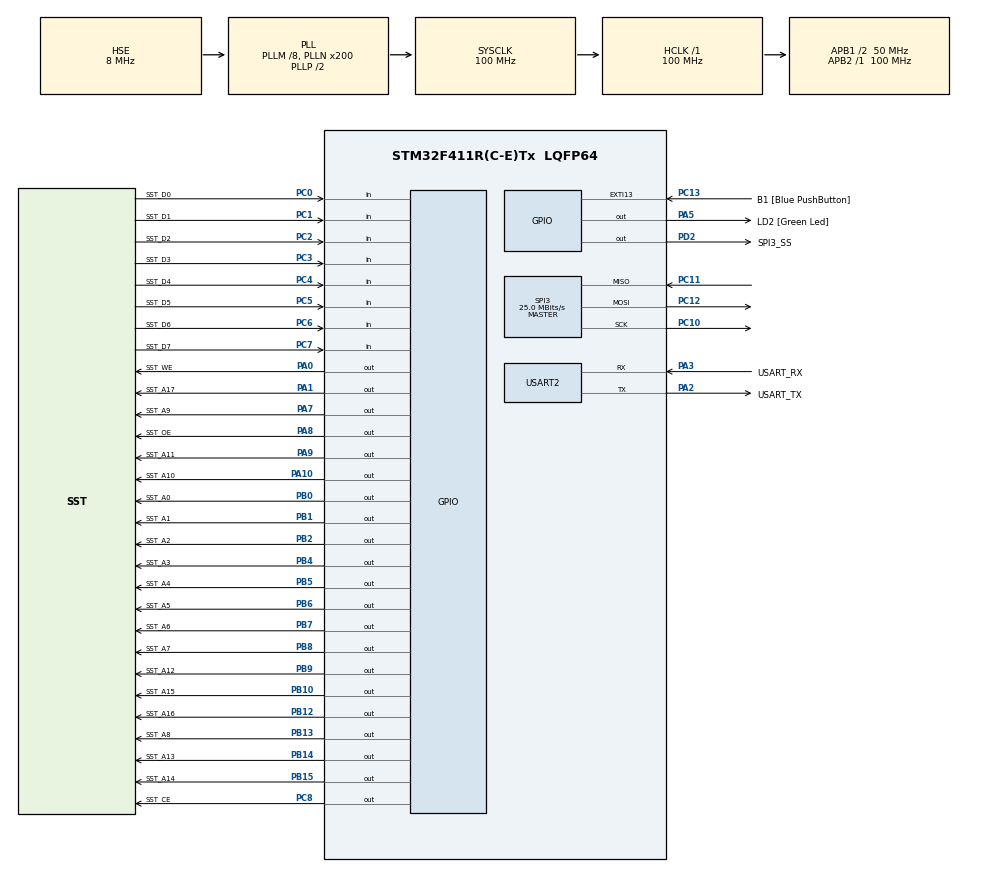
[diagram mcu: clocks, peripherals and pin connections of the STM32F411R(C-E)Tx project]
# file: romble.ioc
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FREERTOS.Tasks01=defaultTask,24,128,StartDefaultTask,Default,NULL,Dynamic,NULL,NULL;cli,40,1024,StartCLITask,Default,NULL,Dynamic,NULL,NULL
FREERTOS.configCHECK_FOR_STACK_OVERFLOW=0
Mcu.Family=STM32F4
Mcu.Name=STM32F411R(C-E)Tx
Mcu.Package=LQFP64
NVIC.PriorityGroup=NVIC_PRIORITYGROUP_4
NVIC.TIM1_BRK_TIM9_IRQn=true\:0\:0\:false\:false\:true\:false\:false\:true
NVIC.TimeBase=TIM1_BRK_TIM9_IRQn
NVIC.TimeBaseIP=TIM9
PA0-WKUP.GPIO_Label=SST_WE
PA0-WKUP.PinState=GPIO_PIN_SET
PA0-WKUP.Signal=GPIO_Output
PA1.GPIO_Label=SST_A17
PA1.Signal=GPIO_Output
PA10.GPIO_Label=SST_A10
PA10.Signal=GPIO_Output
PA13.GPIO_Label=TMS
PA13.Mode=Serial_Wire
PA13.Signal=SYS_JTMS-SWDIO
PA14.GPIO_Label=TCK
PA14.Mode=Serial_Wire
PA14.Signal=SYS_JTCK-SWCLK
PA2.GPIO_Label=USART_TX
PA2.Mode=Asynchronous
PA2.Signal=USART2_TX
PA3.GPIO_Label=USART_RX
PA3.Mode=Asynchronous
PA3.Signal=USART2_RX
PA5.GPIO_Label=LD2 [Green Led]
PA5.Signal=GPIO_Output
PA7.GPIO_Label=SST_A9
PA7.Signal=GPIO_Output
PA8.GPIO_Label=SST_OE
PA8.PinState=GPIO_PIN_SET
PA8.Signal=GPIO_Output
PA9.GPIO_Label=SST_A11
PA9.Signal=GPIO_Output
PB0.GPIO_Label=SST_A0
PB0.Signal=GPIO_Output
PB1.GPIO_Label=SST_A1
PB1.Signal=GPIO_Output
PB10.GPIO_Label=SST_A15
PB10.Signal=GPIO_Output
PB12.GPIO_Label=SST_A16
PB12.Signal=GPIO_Output
PB13.GPIO_Label=SST_A8
PB13.Signal=GPIO_Output
PB14.GPIO_Label=SST_A13
PB14.Signal=GPIO_Output
PB15.GPIO_Label=SST_A14
PB15.Signal=GPIO_Output
PB2.GPIO_Label=SST_A2
PB2.Signal=GPIO_Output
PB3.GPIO_Label=SWO
PB3.Signal=SYS_JTDO-SWO
PB4.GPIO_Label=SST_A3
PB4.Signal=GPIO_Output
PB5.GPIO_Label=SST_A4
PB5.Signal=GPIO_Output
PB6.GPIO_Label=SST_A5
PB6.Signal=GPIO_Output
PB7.GPIO_Label=SST_A6
PB7.Signal=GPIO_Output
PB8.GPIO_Label=SST_A7
PB8.Signal=GPIO_Output
PB9.GPIO_Label=SST_A12
PB9.Signal=GPIO_Output
PC0.GPIO_Label=SST_D0
PC0.GPIO_PuPd=GPIO_PULLUP
PC0.Signal=GPIO_Input
PC1.GPIO_Label=SST_D1
PC1.GPIO_PuPd=GPIO_PULLUP
PC1.Signal=GPIO_Input
PC10.Mode=Full_Duplex_Master
PC10.Signal=SPI3_SCK
PC11.Mode=Full_Duplex_Master
PC11.Signal=SPI3_MISO
PC12.Mode=Full_Duplex_Master
PC12.Signal=SPI3_MOSI
PC13-ANTI_TAMP.GPIO_Label=B1 [Blue PushButton]
PC13-ANTI_TAMP.GPIO_ModeDefaultEXTI=GPIO_MODE_IT_FALLING
PC13-ANTI_TAMP.Signal=GPXTI13
PC14-OSC32_IN.Mode=LSE-External-Oscillator
PC14-OSC32_IN.Signal=RCC_OSC32_IN
PC15-OSC32_OUT.Mode=LSE-External-Oscillator
PC15-OSC32_OUT.Signal=RCC_OSC32_OUT
PC2.GPIO_Label=SST_D2
PC2.GPIO_PuPd=GPIO_PULLUP
PC2.Signal=GPIO_Input
PC3.GPIO_Label=SST_D3
PC3.GPIO_PuPd=GPIO_PULLUP
PC3.Signal=GPIO_Input
PC4.GPIO_Label=SST_D4
PC4.GPIO_PuPd=GPIO_PULLUP
PC4.Signal=GPIO_Input
PC5.GPIO_Label=SST_D5
PC5.GPIO_PuPd=GPIO_PULLUP
PC5.Signal=GPIO_Input
PC6.GPIO_Label=SST_D6
PC6.GPIO_PuPd=GPIO_PULLUP
PC6.Signal=GPIO_Input
PC7.GPIO_Label=SST_D7
PC7.GPIO_PuPd=GPIO_PULLUP
PC7.Signal=GPIO_Input
PC8.GPIO_Label=SST_CE
PC8.PinState=GPIO_PIN_SET
PC8.Signal=GPIO_Output
PD2.GPIO_Label=SPI3_SS
PD2.GPIO_ModeDefaultOutputPP=GPIO_MODE_OUTPUT_OD
PD2.PinState=GPIO_PIN_SET
PD2.Signal=GPIO_Output
PH0\ -\ OSC_IN.Mode=HSE-External-Clock-Source
PH0\ -\ OSC_IN.Signal=RCC_OSC_IN
PH1\ -\ OSC_OUT.Mode=HSE-External-Clock-Source
PH1\ -\ OSC_OUT.Signal=RCC_OSC_OUT
ProjectManager.HeapSize=0x200
ProjectManager.StackSize=0x400
ProjectManager.TargetToolchain=Makefile
RCC.48MHZClocksFreq_Value=20000000
RCC.AHBFreq_Value=100000000
RCC.APB1CLKDivider=RCC_HCLK_DIV2
RCC.APB1Freq_Value=50000000
RCC.APB1TimFreq_Value=100000000
RCC.APB2Freq_Value=100000000
RCC.APB2TimFreq_Value=100000000
RCC.CortexFreq_Value=100000000
RCC.FLatency-AdvancedSettings=FLASH_LATENCY_3
RCC.HCLKFreq_Value=100000000
RCC.HSE_VALUE=8000000
RCC.HSI_VALUE=16000000
RCC.PLLM=8
RCC.PLLN=200
RCC.PLLQ=10
RCC.PLLSourceVirtual=RCC_PLLSOURCE_HSE
RCC.SYSCLKFreq_VALUE=100000000
RCC.SYSCLKSource=RCC_SYSCLKSOURCE_PLLCLK
RCC.VCOOutputFreq_Value=200000000
SPI3.CalculateBaudRate=25.0 MBits/s
SPI3.Direction=SPI_DIRECTION_2LINES
SPI3.Mode=SPI_MODE_MASTER
SPI3.VirtualType=VM_MASTER
USART2.VirtualMode=VM_ASYNC
VP_FREERTOS_VS_CMSIS_V2.Mode=CMSIS_V2
VP_SYS_VS_tim9.Mode=TIM9
board=NUCLEO-F411RE

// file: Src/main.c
/* USER CODE BEGIN Header */
/**
  ******************************************************************************
  * @file           : main.c
  * @brief          : Main program body
  ******************************************************************************
  * @attention
  *
  * <h2><center>&copy; Copyright (c) 2020 STMicroelectronics.
  * All rights reserved.</center></h2>
  *
  * This software component is licensed by ST under Ultimate Liberty license
  * SLA0044, the "License"; You may not use this file except in compliance with
  * the License. You may obtain a copy of the License at:
  *                             www.st.com/SLA0044
  *
  ******************************************************************************
  */
/* USER CODE END Header */

#include "main.h"
#include "cmsis_os.h"

/* USER CODE BEGIN Includes */
#include "cli.h"

/* USER CODE END Includes */

SPI_HandleTypeDef hspi3;

UART_HandleTypeDef huart2;

osThreadId_t defaultTaskHandle;
osThreadId_t cliHandle;

void SystemClock_Config(void);
static void MX_GPIO_Init(void);
static void MX_USART2_UART_Init(void);
static void MX_SPI3_Init(void);
void StartDefaultTask(void *argument);
void StartCLITask(void *argument);

int main(void)
{

  /* MCU Configuration--------------------------------------------------------*/

  /* Reset of all peripherals, Initializes the Flash interface and the Systick. */
  HAL_Init();

  /* Configure the system clock */
  SystemClock_Config();

  /* Initialize all configured peripherals */
  MX_GPIO_Init();
  MX_USART2_UART_Init();
  MX_SPI3_Init();

  osKernelInitialize();

  /* Create the thread(s) */
  /* definition and creation of defaultTask */
  const osThreadAttr_t defaultTask_attributes = {
    .name = "defaultTask",
    .priority = (osPriority_t) osPriorityNormal,
    .stack_size = 128
  };
  defaultTaskHandle = osThreadNew(StartDefaultTask, NULL, &defaultTask_attributes);

  /* definition and creation of cli */
  const osThreadAttr_t cli_attributes = {
    .name = "cli",
    .priority = (osPriority_t) osPriorityHigh,
    .stack_size = 1024
  };
  cliHandle = osThreadNew(StartCLITask, NULL, &cli_attributes);

  /* Start scheduler */
  osKernelStart();

  /* We should never get here as control is now taken by the scheduler */

  /* Infinite loop */
  while (1)
  {

  }
}

void SystemClock_Config(void)
{
  RCC_OscInitTypeDef RCC_OscInitStruct = {0};
  RCC_ClkInitTypeDef RCC_ClkInitStruct = {0};

  /** Configure the main internal regulator output voltage
  */
  __HAL_RCC_PWR_CLK_ENABLE();
  __HAL_PWR_VOLTAGESCALING_CONFIG(PWR_REGULATOR_VOLTAGE_SCALE1);
  /** Initializes the CPU, AHB and APB busses clocks
  */
  RCC_OscInitStruct.OscillatorType = RCC_OSCILLATORTYPE_HSE;
  RCC_OscInitStruct.HSEState = RCC_HSE_BYPASS;
  RCC_OscInitStruct.PLL.PLLState = RCC_PLL_ON;
  RCC_OscInitStruct.PLL.PLLSource = RCC_PLLSOURCE_HSE;
  RCC_OscInitStruct.PLL.PLLM = 8;
  RCC_OscInitStruct.PLL.PLLN = 200;
  RCC_OscInitStruct.PLL.PLLP = RCC_PLLP_DIV2;
  RCC_OscInitStruct.PLL.PLLQ = 10;
  if (HAL_RCC_OscConfig(&RCC_OscInitStruct) != HAL_OK)
  {
    Error_Handler();
  }
  /** Initializes the CPU, AHB and APB busses clocks
  */
  RCC_ClkInitStruct.ClockType = RCC_CLOCKTYPE_HCLK|RCC_CLOCKTYPE_SYSCLK
                              |RCC_CLOCKTYPE_PCLK1|RCC_CLOCKTYPE_PCLK2;
  RCC_ClkInitStruct.SYSCLKSource = RCC_SYSCLKSOURCE_PLLCLK;
  RCC_ClkInitStruct.AHBCLKDivider = RCC_SYSCLK_DIV1;
  RCC_ClkInitStruct.APB1CLKDivider = RCC_HCLK_DIV2;
  RCC_ClkInitStruct.APB2CLKDivider = RCC_HCLK_DIV1;

  if (HAL_RCC_ClockConfig(&RCC_ClkInitStruct, FLASH_LATENCY_3) != HAL_OK)
  {
    Error_Handler();
  }
}

static void MX_SPI3_Init(void)
{

  /* SPI3 parameter configuration*/
  hspi3.Instance = SPI3;
  hspi3.Init.Mode = SPI_MODE_MASTER;
  hspi3.Init.Direction = SPI_DIRECTION_2LINES;
  hspi3.Init.DataSize = SPI_DATASIZE_8BIT;
  hspi3.Init.CLKPolarity = SPI_POLARITY_LOW;
  hspi3.Init.CLKPhase = SPI_PHASE_1EDGE;
  hspi3.Init.NSS = SPI_NSS_SOFT;
  hspi3.Init.BaudRatePrescaler = SPI_BAUDRATEPRESCALER_128;
  hspi3.Init.FirstBit = SPI_FIRSTBIT_MSB;
  hspi3.Init.TIMode = SPI_TIMODE_DISABLE;
  hspi3.Init.CRCCalculation = SPI_CRCCALCULATION_DISABLE;
  hspi3.Init.CRCPolynomial = 10;
  if (HAL_SPI_Init(&hspi3) != HAL_OK)
  {
    Error_Handler();
  }

}

static void MX_USART2_UART_Init(void)
{

  huart2.Instance = USART2;
  huart2.Init.BaudRate = 115200;
  huart2.Init.WordLength = UART_WORDLENGTH_8B;
  huart2.Init.StopBits = UART_STOPBITS_1;
  huart2.Init.Parity = UART_PARITY_NONE;
  huart2.Init.Mode = UART_MODE_TX_RX;
  huart2.Init.HwFlowCtl = UART_HWCONTROL_NONE;
  huart2.Init.OverSampling = UART_OVERSAMPLING_16;
  if (HAL_UART_Init(&huart2) != HAL_OK)
  {
    Error_Handler();
  }

}

static void MX_GPIO_Init(void)
{
  GPIO_InitTypeDef GPIO_InitStruct = {0};

  /* GPIO Ports Clock Enable */
  __HAL_RCC_GPIOC_CLK_ENABLE();
  __HAL_RCC_GPIOH_CLK_ENABLE();
  __HAL_RCC_GPIOA_CLK_ENABLE();
  __HAL_RCC_GPIOB_CLK_ENABLE();
  __HAL_RCC_GPIOD_CLK_ENABLE();

  /*Configure GPIO pin Output Level */
  HAL_GPIO_WritePin(GPIOA, SST_WE_Pin|SST_OE_Pin, GPIO_PIN_SET);

  /*Configure GPIO pin Output Level */
  HAL_GPIO_WritePin(GPIOA, SST_A17_Pin|LD2_Pin|SST_A9_Pin|SST_A11_Pin
                          |SST_A10_Pin, GPIO_PIN_RESET);

  /*Configure GPIO pin Output Level */
  HAL_GPIO_WritePin(GPIOB, SST_A0_Pin|SST_A1_Pin|SST_A2_Pin|SST_A15_Pin
                          |SST_A16_Pin|SST_A8_Pin|SST_A13_Pin|SST_A14_Pin
                          |SST_A3_Pin|SST_A4_Pin|SST_A5_Pin|SST_A6_Pin
                          |SST_A7_Pin|SST_A12_Pin, GPIO_PIN_RESET);

  /*Configure GPIO pin Output Level */
  HAL_GPIO_WritePin(SST_CE_GPIO_Port, SST_CE_Pin, GPIO_PIN_SET);

  /*Configure GPIO pin Output Level */
  HAL_GPIO_WritePin(SPI3_SS_GPIO_Port, SPI3_SS_Pin, GPIO_PIN_SET);

  /*Configure GPIO pin : B1_Pin */
  GPIO_InitStruct.Pin = B1_Pin;
  GPIO_InitStruct.Mode = GPIO_MODE_IT_FALLING;
  GPIO_InitStruct.Pull = GPIO_NOPULL;
  HAL_GPIO_Init(B1_GPIO_Port, &GPIO_InitStruct);

  /*Configure GPIO pins : SST_D0_Pin SST_D1_Pin SST_D2_Pin SST_D3_Pin
                           SST_D4_Pin SST_D5_Pin SST_D6_Pin SST_D7_Pin */
  GPIO_InitStruct.Pin = SST_D0_Pin|SST_D1_Pin|SST_D2_Pin|SST_D3_Pin
                          |SST_D4_Pin|SST_D5_Pin|SST_D6_Pin|SST_D7_Pin;
  GPIO_InitStruct.Mode = GPIO_MODE_INPUT;
  GPIO_InitStruct.Pull = GPIO_PULLUP;
  HAL_GPIO_Init(GPIOC, &GPIO_InitStruct);

  /*Configure GPIO pins : SST_WE_Pin SST_A17_Pin LD2_Pin SST_A9_Pin
                           SST_OE_Pin SST_A11_Pin SST_A10_Pin */
  GPIO_InitStruct.Pin = SST_WE_Pin|SST_A17_Pin|LD2_Pin|SST_A9_Pin
                          |SST_OE_Pin|SST_A11_Pin|SST_A10_Pin;
  GPIO_InitStruct.Mode = GPIO_MODE_OUTPUT_PP;
  GPIO_InitStruct.Pull = GPIO_NOPULL;
  GPIO_InitStruct.Speed = GPIO_SPEED_FREQ_LOW;
  HAL_GPIO_Init(GPIOA, &GPIO_InitStruct);

  /*Configure GPIO pins : SST_A0_Pin SST_A1_Pin SST_A2_Pin SST_A15_Pin
                           SST_A16_Pin SST_A8_Pin SST_A13_Pin SST_A14_Pin
                           SST_A3_Pin SST_A4_Pin SST_A5_Pin SST_A6_Pin
                           SST_A7_Pin SST_A12_Pin */
  GPIO_InitStruct.Pin = SST_A0_Pin|SST_A1_Pin|SST_A2_Pin|SST_A15_Pin
                          |SST_A16_Pin|SST_A8_Pin|SST_A13_Pin|SST_A14_Pin
                          |SST_A3_Pin|SST_A4_Pin|SST_A5_Pin|SST_A6_Pin
                          |SST_A7_Pin|SST_A12_Pin;
  GPIO_InitStruct.Mode = GPIO_MODE_OUTPUT_PP;
  GPIO_InitStruct.Pull = GPIO_NOPULL;
  GPIO_InitStruct.Speed = GPIO_SPEED_FREQ_LOW;
  HAL_GPIO_Init(GPIOB, &GPIO_InitStruct);

  /*Configure GPIO pin : SST_CE_Pin */
  GPIO_InitStruct.Pin = SST_CE_Pin;
  GPIO_InitStruct.Mode = GPIO_MODE_OUTPUT_PP;
  GPIO_InitStruct.Pull = GPIO_NOPULL;
  GPIO_InitStruct.Speed = GPIO_SPEED_FREQ_LOW;
  HAL_GPIO_Init(SST_CE_GPIO_Port, &GPIO_InitStruct);

  /*Configure GPIO pin : SPI3_SS_Pin */
  GPIO_InitStruct.Pin = SPI3_SS_Pin;
  GPIO_InitStruct.Mode = GPIO_MODE_OUTPUT_OD;
  GPIO_InitStruct.Pull = GPIO_NOPULL;
  GPIO_InitStruct.Speed = GPIO_SPEED_FREQ_LOW;
  HAL_GPIO_Init(SPI3_SS_GPIO_Port, &GPIO_InitStruct);

}

void StartDefaultTask(void *argument)
{
  /* USER CODE BEGIN 5 */
  /* Infinite loop */
  for(;;)
  {
    osDelay(100000);
  }
  /* USER CODE END 5 */
}

void StartCLITask(void *argument)
{
  /* USER CODE BEGIN StartCLITask */
    static CLI_SetupTypeDef cli_config = {
        &huart2,
        {
            &hspi3,
            SPI3_SS_GPIO_Port,
            SPI3_SS_Pin
        }
    };
    cli_loop(&cli_config);
  /* USER CODE END StartCLITask */
}

void HAL_TIM_PeriodElapsedCallback(TIM_HandleTypeDef *htim)
{
  if (htim->Instance == TIM9) {
    HAL_IncTick();
  }
}

void Error_Handler(void)
{
}

/************************ (C) COPYRIGHT STMicroelectronics *****END OF FILE****/
